VERSION ""

NS_ :

BS_:

BU_: Cockpit PERS Vector__XXX

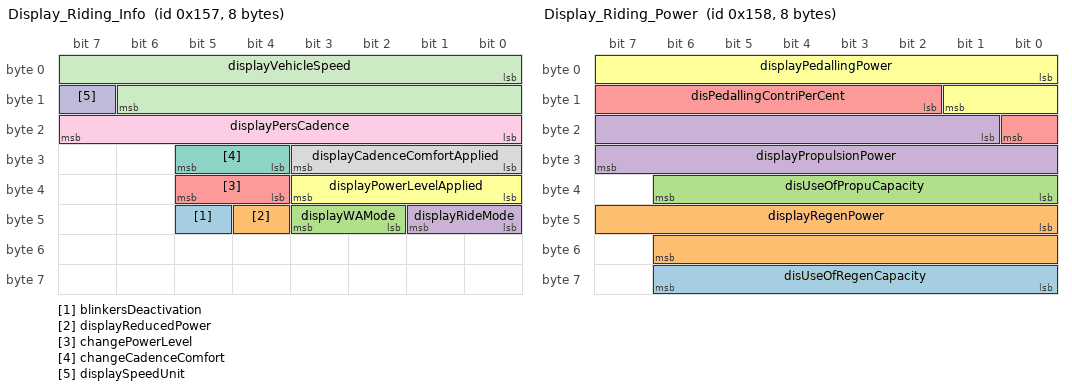
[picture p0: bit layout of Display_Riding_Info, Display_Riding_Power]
BO_ 343 Display_Riding_Info: 8 PERS
 SG_ blinkersDeactivation : 45|1@1+ (1,0) [0|1] "-"  Cockpit
 SG_ displayReducedPower : 44|1@1+ (1,0) [0|1] "-"  Cockpit
 SG_ displayWAMode : 42|2@1+ (1,0) [0|3] "-"  Cockpit
 SG_ displayRideMode : 40|2@1+ (1,0) [0|3] "-"  Cockpit
 SG_ changePowerLevel : 36|2@1+ (1,0) [0|3] "-"  Cockpit
 SG_ displayPowerLevelApplied : 32|4@1+ (1,0) [0|15] "-"  Cockpit
 SG_ changeCadenceComfort : 28|2@1+ (1,0) [0|3] "-"  Cockpit
 SG_ displayCadenceComfortApplied : 24|4@1+ (1,0) [0|15] "-"  Cockpit
 SG_ displayPersCadence : 16|8@1+ (1,0) [0|255] "rpm"  Cockpit
 SG_ displaySpeedUnit : 15|1@1+ (1,0) [0|1] ""  Cockpit
 SG_ displayVehicleSpeed : 0|15@1+ (0.01,-40) [-40|80] "km/h"  Cockpit

BO_ 344 Display_Riding_Power: 8 PERS
 SG_ disUseOfRegenCapacity : 56|7@1+ (1,0) [0|100] "%"  Cockpit
 SG_ displayRegenPower : 40|15@1+ (1,0) [0|32767] "W"  Cockpit
 SG_ disUseOfPropuCapacity : 32|7@1+ (1,0) [0|100] "%"  Cockpit
 SG_ displayPropulsionPower : 17|15@1+ (1,0) [0|32767] "W"  Cockpit
 SG_ disPedallingContriPerCent : 10|7@1+ (1,0) [0|100] "%"  Cockpit
 SG_ displayPedallingPower : 0|10@1+ (1,0) [0|1024] "W"  Cockpit

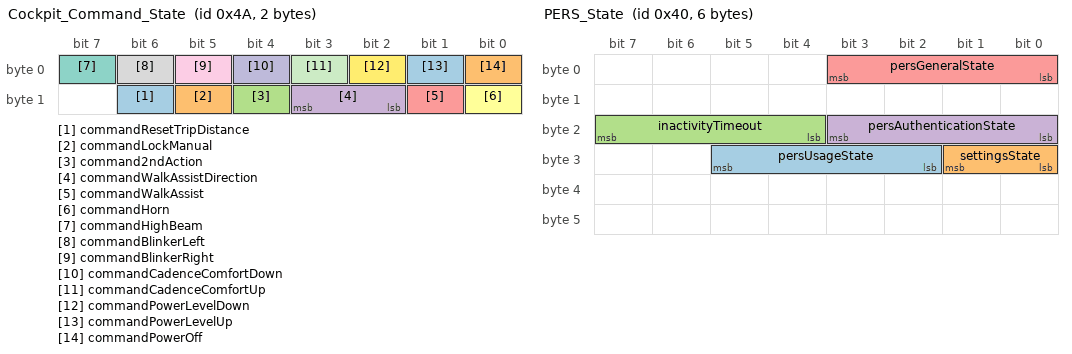
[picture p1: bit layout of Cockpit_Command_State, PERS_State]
BO_ 74 Cockpit_Command_State: 2 Cockpit
 SG_ commandResetTripDistance : 14|1@1+ (1,0) [0|1] ""  PERS
 SG_ commandLockManual : 13|1@1+ (1,0) [0|1] ""  PERS
 SG_ command2ndAction : 12|1@1+ (1,0) [0|1] ""  PERS
 SG_ commandWalkAssistDirection : 10|2@1+ (1,0) [0|3] ""  PERS
 SG_ commandWalkAssist : 9|1@1+ (1,0) [0|1] ""  PERS
 SG_ commandHorn : 8|1@1+ (1,0) [0|1] ""  PERS
 SG_ commandHighBeam : 7|1@1+ (1,0) [0|1] ""  PERS
 SG_ commandBlinkerLeft : 6|1@1+ (1,0) [0|1] ""  PERS
 SG_ commandBlinkerRight : 5|1@1+ (1,0) [0|1] ""  PERS
 SG_ commandCadenceComfortDown : 4|1@1+ (1,0) [0|1] ""  PERS
 SG_ commandCadenceComfortUp : 3|1@1+ (1,0) [0|1] ""  PERS
 SG_ commandPowerLevelDown : 2|1@1+ (1,0) [0|1] ""  PERS
 SG_ commandPowerLevelUp : 1|1@1+ (1,0) [0|1] ""  PERS
 SG_ commandPowerOff : 0|1@1+ (1,0) [0|1] ""  PERS

BO_ 64 PERS_State: 6 PERS
 SG_ persUsageState : 26|4@1+ (1,0) [0|15] "-"  Cockpit
 SG_ settingsState : 24|2@1+ (1,0) [0|3] "-"  Cockpit
 SG_ inactivityTimeout : 20|4@1+ (1,0) [0|15] "sec"  Cockpit
 SG_ persAuthenticationState : 16|4@1+ (1,0) [0|15] ""  Cockpit
 SG_ persGeneralState : 0|4@1+ (1,0) [0|15] ""  Cockpit

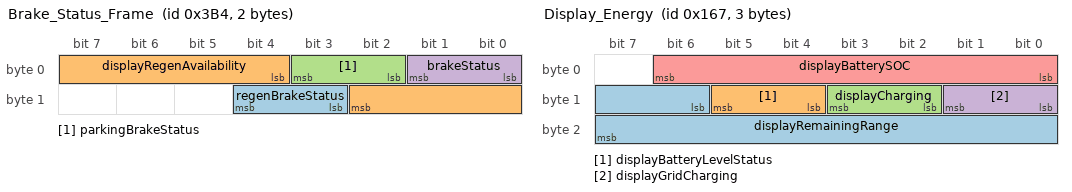
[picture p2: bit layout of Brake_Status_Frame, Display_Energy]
BO_ 948 Brake_Status_Frame: 2 PERS
 SG_ regenBrakeStatus : 11|2@1+ (1,0) [0|3] "-"  Cockpit
 SG_ displayRegenAvailability : 4|7@1+ (1,0) [0|127] "%"  Cockpit
 SG_ parkingBrakeStatus : 2|2@1+ (1,0) [0|3] "-"  Cockpit
 SG_ brakeStatus : 0|2@1+ (1,0) [0|3] "-"  Cockpit

BO_ 952 Odometer: 4 PERS
 SG_ displayOdometer : 0|32@1+ (0.001,0) [0|4294970] "km"  Cockpit

BO_ 953 Trip_info: 4 PERS
 SG_ tripDistance : 0|32@1+ (0.001,0) [0|4294970] "km"  Cockpit

BO_ 359 Display_Energy: 3 PERS
 SG_ displayRemainingRange : 14|10@1+ (1,0) [0|1023] "km"  Cockpit
 SG_ displayBatteryLevelStatus : 12|2@1+ (1,0) [0|3] "-"  Cockpit
 SG_ displayCharging : 10|2@1+ (1,0) [0|3] "-"  Cockpit
 SG_ displayGridCharging : 8|2@1+ (1,0) [0|3] "-"  Cockpit
 SG_ displayBatterySOC : 0|7@1+ (1,0) [0|127] "%"  Cockpit

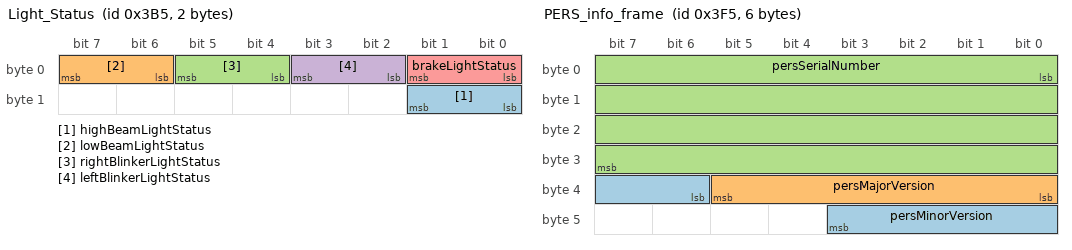
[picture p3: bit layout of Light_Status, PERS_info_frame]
BO_ 949 Light_Status: 2 PERS
 SG_ highBeamLightStatus : 8|2@1+ (1,0) [0|3] ""  Cockpit
 SG_ lowBeamLightStatus : 6|2@1+ (1,0) [0|3] ""  Cockpit
 SG_ rightBlinkerLightStatus : 4|2@1+ (1,0) [0|3] ""  Cockpit
 SG_ leftBlinkerLightStatus : 2|2@1+ (1,0) [0|3] ""  Cockpit
 SG_ brakeLightStatus : 0|2@1+ (1,0) [0|3] ""  Cockpit

BO_ 950 Service_Status_Frame: 1 PERS
 SG_ n4GStatus : 2|2@1+ (1,0) [0|3] "-"  Cockpit
 SG_ bluetoothStatus : 0|2@1+ (1,0) [0|3] "-"  Cockpit

BO_ 1013 PERS_info_frame: 6 PERS
 SG_ persMinorVersion : 38|6@1+ (1,0) [0|63] "-"  Cockpit
 SG_ persMajorVersion : 32|6@1+ (1,0) [0|63] "-"  Cockpit
 SG_ persSerialNumber : 0|32@1+ (1,0) [0|4294967295] "-"  Cockpit

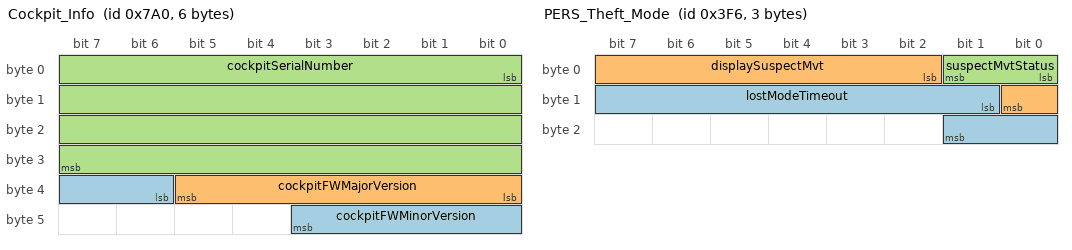
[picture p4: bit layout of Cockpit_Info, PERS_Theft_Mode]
BO_ 1952 Cockpit_Info: 6 Cockpit
 SG_ cockpitFWMinorVersion : 38|6@1+ (1,0) [0|63] "-"  PERS
 SG_ cockpitFWMajorVersion : 32|6@1+ (1,0) [0|63] "-"  PERS
 SG_ cockpitSerialNumber : 0|32@1+ (1,0) [0|4294967295] "-"  PERS

BO_ 1014 PERS_Theft_Mode: 3 PERS
 SG_ lostModeTimeout : 9|9@1+ (1,0) [0|511] "sec"  Cockpit
 SG_ displaySuspectMvt : 2|7@1+ (1,0) [0|100] "%"  Cockpit
 SG_ suspectMvtStatus : 0|2@1+ (1,0) [0|3] ""  Cockpit

BO_ 951 PERS_time_frame: 4 PERS
 SG_ timestamp : 0|32@1+ (1,0) [0|4294967295] "s"  Cockpit

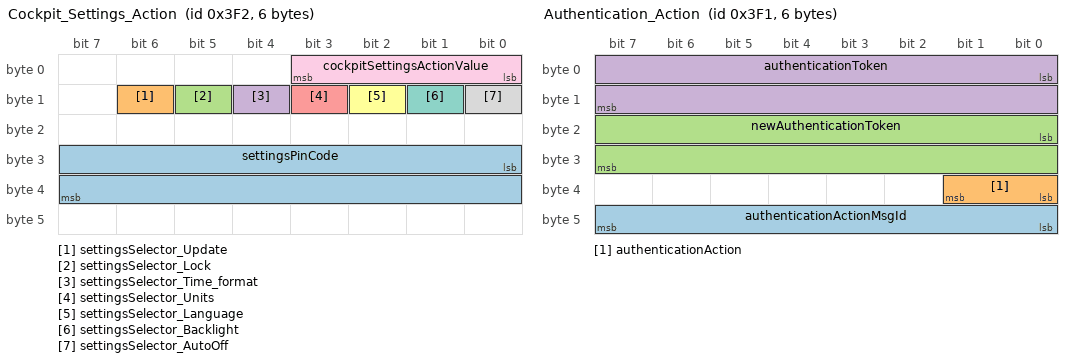
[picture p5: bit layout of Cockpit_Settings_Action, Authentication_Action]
BO_ 1010 Cockpit_Settings_Action: 6 Cockpit
 SG_ settingsPinCode : 24|16@1+ (1,0) [0|65535] "-"  PERS
 SG_ settingsSelector_Update : 14|1@1+ (1,0) [0|1] ""  PERS
 SG_ settingsSelector_Lock : 13|1@1+ (1,0) [0|1] ""  PERS
 SG_ settingsSelector_Time_format : 12|1@1+ (1,0) [0|1] ""  PERS
 SG_ settingsSelector_Units : 11|1@1+ (1,0) [0|1] ""  PERS
 SG_ settingsSelector_Language : 10|1@1+ (1,0) [0|1] ""  PERS
 SG_ settingsSelector_Backlight : 9|1@1+ (1,0) [0|1] ""  PERS
 SG_ settingsSelector_AutoOff : 8|1@1+ (1,0) [0|1] "-"  PERS
 SG_ cockpitSettingsActionValue : 0|4@1+ (1,0) [0|15] "-"  PERS

BO_ 995 Cockpit_Settings_Action_State: 6 PERS
 SG_ displayUpdateConfig m0 : 44|2@1+ (1,0) [0|3] "-"  Cockpit
 SG_ displayLockConfig m0 : 42|2@1+ (1,0) [0|1] "-"  Cockpit
 SG_ displayTimeFormat m0 : 41|1@1+ (1,0) [0|1] "-"  Cockpit
 SG_ displaySpeedUnitConfig m0 : 40|1@1+ (1,0) [0|1] "-"  Cockpit
 SG_ displayLanguage m0 : 36|4@1+ (1,0) [0|15] "-"  Cockpit
 SG_ displayBacklightConfig m0 : 32|4@1+ (1,0) [0|15] "-"  Cockpit
 SG_ displayAutoOffTimeout m0 : 24|8@1+ (1,0) [0|63] "minutes"  Cockpit
 SG_ settingsSelectorRX_Update : 14|1@1+ (1,0) [0|1] ""  Cockpit
 SG_ settingsSelectorRX_Lock : 13|1@1+ (1,0) [0|1] ""  Cockpit
 SG_ settingsSelectorRX_Time_format : 12|1@1+ (1,0) [0|1] ""  Cockpit
 SG_ settingsSelectorRX_Units : 11|1@1+ (1,0) [0|1] ""  Cockpit
 SG_ settingsSelectorRX_Language : 10|1@1+ (1,0) [0|1] ""  Cockpit
 SG_ settingsSelectorRX_Backlight : 9|1@1+ (1,0) [0|1] ""  Cockpit
 SG_ settingsSelectorRX_AutoOff : 8|1@1+ (1,0) [0|1] "-"  Cockpit
 SG_ cockpitSettingPage M : 4|4@1+ (1,0) [0|15] "-"  Cockpit
 SG_ cockpitActionSettingResult : 0|4@1+ (1,0) [0|15] "-"  Cockpit

BO_ 1009 Authentication_Action: 6 Cockpit
 SG_ authenticationActionMsgId : 40|8@1+ (1,0) [0|255] ""  PERS
 SG_ authenticationAction : 32|2@1+ (1,0) [0|3] ""  PERS
 SG_ newAuthenticationToken : 16|16@1+ (1,0) [0|65535] ""  PERS
 SG_ authenticationToken : 0|16@1+ (1,0) [0|65535] ""  PERS

BO_ 993 Authentication_Action_Result: 2 PERS
 SG_ authenticationActionResult : 8|8@1+ (1,0) [0|255] ""  Cockpit
 SG_ authenticationReceivedMsgId : 0|8@1+ (1,0) [0|255] ""  Cockpit

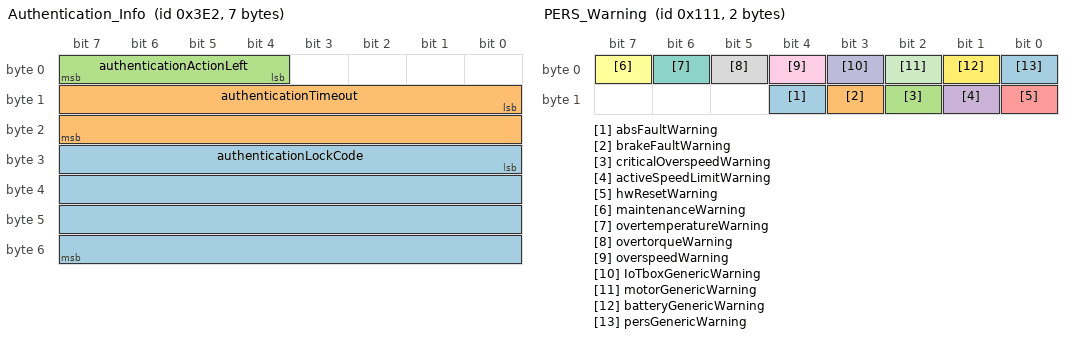
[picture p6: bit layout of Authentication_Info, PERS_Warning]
BO_ 994 Authentication_Info: 7 PERS
 SG_ authenticationLockCode : 24|32@1+ (1,0) [0|4294967295] "-"  Cockpit
 SG_ authenticationTimeout : 8|16@1+ (1,0) [0|65535] "sec"  Cockpit
 SG_ authenticationActionLeft : 4|4@1+ (1,0) [0|16] "-"  Cockpit

BO_ 1011 Recuperation_Action: 8 Cockpit
 SG_ recuperativeToken : 0|64@1+ (1,0) [0|4294967295] ""  PERS

BO_ 1956 Cockpit_Fw_Update_Status: 3 Cockpit
 SG_ fwUpdateLastReceivedBlock : 8|16@1+ (1,0) [0|65535] "-"  PERS
 SG_ fwUpdateStatus : 0|8@1+ (1,0) [0|255] ""  PERS

BO_ 1957 Cockpit_Fw_Update_Command: 5 PERS
 SG_ fwUpdatedBlockCRC16 m6 : 24|16@1+ (1,0) [0|65535] "-"  Cockpit
 SG_ fwUpdateBlockSize m5 : 24|12@1+ (1,1) [1|4096] "-"  Cockpit
 SG_ fwUpdatedBlockId m6 : 8|16@1+ (1,0) [0|65535] "-"  Cockpit
 SG_ fwUpdateBlockId m5 : 8|16@1+ (1,0) [0|65535] "-"  Cockpit
 SG_ fwUpdateCommand M : 0|8@1+ (1,0) [0|32] ""  Cockpit

BO_ 1958 Cockpit_Fw_Update_Binary: 8 PERS
 SG_ fwUpdateBinaryData : 0|64@1+ (1,0) [0|18446744073709551615] "-"  Cockpit

BO_ 1959 Cockpit_Fw_Update_Ack: 2 Cockpit
 SG_ fwUpdateComandResult : 8|4@1+ (1,0) [0|15] "-"  PERS
 SG_ fwUpdateCommandReceived : 0|8@1+ (1,0) [0|255] ""  PERS

BO_ 273 PERS_Warning: 2 PERS
 SG_ absFaultWarning : 12|1@1+ (1,0) [0|1] "-"  Cockpit
 SG_ brakeFaultWarning : 11|1@1+ (1,0) [0|1] "-"  Cockpit
 SG_ criticalOverspeedWarning : 10|1@1+ (1,0) [0|1] "-"  Cockpit
 SG_ activeSpeedLimitWarning : 9|1@1+ (1,0) [0|1] "-"  Cockpit
 SG_ hwResetWarning : 8|1@1+ (1,0) [0|1] "-"  Cockpit
 SG_ maintenanceWarning : 7|1@1+ (1,0) [0|1] "-"  Cockpit
 SG_ overtemperatureWarning : 6|1@1+ (1,0) [0|1] "-"  Cockpit
 SG_ overtorqueWarning : 5|1@1+ (1,0) [0|1] ""  Cockpit
 SG_ overspeedWarning : 4|1@1+ (1,0) [0|1] "-"  Cockpit
 SG_ IoTboxGenericWarning : 3|1@1+ (1,0) [0|1] "-"  Cockpit
 SG_ motorGenericWarning : 2|1@1+ (1,0) [0|1] "-"  Cockpit
 SG_ batteryGenericWarning : 1|1@1+ (1,0) [0|1] "-"  Cockpit
 SG_ persGenericWarning : 0|1@1+ (1,0) [0|1] "-"  Cockpit

BO_ 272 PERS_Error: 1 PERS
 SG_ persGenericError : 0|1@1+ (1,0) [0|1] "-"  Cockpit

BO_ 1955 Cockpit_Heartbeat: 2 Cockpit
 SG_ cockpitHeartbeat : 0|16@1+ (1,0) [0|65535] "-"  PERS

BO_ 1920 PERS_Heartbeat: 2 PERS
 SG_ PERSHeartbeat : 0|16@1+ (1,0) [0|65535] "-"  Vector__XXX

CM_ SG_ 343 blinkersDeactivation "Set to DEACTIVATION when an automatic deactivation of blinkers is required by the PERS.";
CM_ SG_ 343 displayReducedPower "1 - Automatic reduction of propulsion power is applied (active speed limitation, assistance cut-off, propulsion cutoff, battery discharge).";
CM_ SG_ 343 changeCadenceComfort "0 - No†commandCadenceComfortUp or Down have been received 1 - commandCadenceComfortUp or Down have been received but no cadence comfort change applied 2- commandCadenceComfortUp or Down received and cadence comfort change applied";
CM_ SG_ 343 displaySpeedUnit "Speed units, 0-kph 1-mph";
CM_ SG_ 343 displayVehicleSpeed "Speed of the vehicle estimated by the PERS in km/h";
CM_ SG_ 344 disUseOfRegenCapacity "Regen Torque Availability";
CM_ SG_ 344 disUseOfPropuCapacity "Percentage of current vehicule force on its maximum capacity";
CM_ SG_ 344 disPedallingContriPerCent "Percentage of the contribution of the pedalling on vehicule force";
CM_ SG_ 64 persUsageState "ALARM : suspect activity detected by the PERS LOST : Theft confirmed by the user NEUTRALIZED : unusable (e.g. critical error)";
CM_ SG_ 64 settingsState "0 : the user can't enter in the settings menu 3 : the user can enter in the settings menu";
CM_ SG_ 64 inactivityTimeout "Timeout of inactivity.  Necessary for automatic exit of ADM.";
CM_ SG_ 64 persGeneralState "The ON/OFF state of PERS";
CM_ SG_ 948 regenBrakeStatus "Not use : no regen brake Manual available: regen brake requested by the user and available Manual not available : regen brake requested by the user but not available Auto : regen brake activated by the propulsion motor (overspeed)";
CM_ SG_ 948 displayRegenAvailability "Regen brake capability availability in %";
CM_ SG_ 948 parkingBrakeStatus "Brake disable : parking brake not activated Brake enable : parking brake activated";
CM_ SG_ 948 brakeStatus "Brake disable : all brake systems are deactivated Brake enable : a brake system is activated (can be mechanical brake or regen brake)";
CM_ SG_ 953 tripDistance "distance resetable by the user for trip distance feedback";
CM_ SG_ 359 displayRemainingRange "Estimated remaining range";
CM_ SG_ 359 displayGridCharging "Charging on Grid.";
CM_ SG_ 359 displayBatterySOC "in % of SOC";
CM_ SG_ 1013 persMinorVersion "PERS minor version";
CM_ SG_ 1013 persMajorVersion "PERS major version";
CM_ SG_ 1013 persSerialNumber "Serial number of the PERS";
CM_ SG_ 1952 cockpitFWMinorVersion "Cockpit FW minor version";
CM_ SG_ 1952 cockpitFWMajorVersion "Cockpit FW major version";
CM_ SG_ 1952 cockpitSerialNumber "Serial number of the cockpit";
CM_ SG_ 1014 lostModeTimeout "Timer before switching in LOST mode. max : 8min30s";
CM_ SG_ 1014 displaySuspectMvt "Percentage of on going movement comapred to the limit before entering in ALARM mode.† 0% : no ongoing movement 100% : movement max before entering ALARM mode reached.";
CM_ SG_ 1014 suspectMvtStatus "Indicate if the PERS detects a movement which can trigger the ALARM mode";
CM_ SG_ 951 timestamp "Number of seconds elapsed since 01/01/2000 00:00:00. timestamp 2000 epoch";
CM_ SG_ 1010 settingsPinCode "Current authentification pin code. 0 if not required for current action.";
CM_ SG_ 1010 settingsSelector_Update "The request is applied on this setting";
CM_ SG_ 1010 settingsSelector_Lock "The request is applied on this setting";
CM_ SG_ 1010 settingsSelector_Time_format "The request is applied on this setting";
CM_ SG_ 1010 settingsSelector_Units "The request is applied on this setting";
CM_ SG_ 1010 settingsSelector_Language "The request is applied on this setting";
CM_ SG_ 1010 settingsSelector_Backlight "The request is applied on this setting";
CM_ SG_ 1010 settingsSelector_AutoOff "The request is applied on this setting";
CM_ SG_ 995 displayUpdateConfig "Unsupported : manual update configuration is only supported by the APP.";
CM_ SG_ 995 displayLanguage "Fran√ßais English";
CM_ SG_ 995 displayBacklightConfig "Level of brightness";
CM_ SG_ 995 displayAutoOffTimeout "Auto-off timeout value in minutes";
CM_ SG_ 995 settingsSelectorRX_Update "The request was applied on this setting";
CM_ SG_ 995 settingsSelectorRX_Lock "The request was applied on this setting";
CM_ SG_ 995 settingsSelectorRX_Time_format "The request was applied on this setting";
CM_ SG_ 995 settingsSelectorRX_Units "The request was applied on this setting";
CM_ SG_ 995 settingsSelectorRX_Language "The request was applied on this setting";
CM_ SG_ 995 settingsSelectorRX_Backlight "The request was applied on this setting";
CM_ SG_ 995 settingsSelectorRX_AutoOff "The request was applied on this setting";
CM_ SG_ 995 cockpitSettingPage "multiplexer : settings information page to transmit";
CM_ SG_ 995 cockpitActionSettingResult "For settings that required PIN code enter :† PIN_FAULT : error in code PIN and request new PIN enter RESULT_KO : Code PIN error on the last authorizable PIN enter";
CM_ SG_ 1009 authenticationActionMsgId "Message ID of auhentication action message.";
CM_ SG_ 1009 authenticationAction "Action to execute on reception of this message";
CM_ SG_ 1009 newAuthenticationToken "New authentication token";
CM_ SG_ 1009 authenticationToken "Authentication token";
CM_ SG_ 993 authenticationReceivedMsgId "Message ID of auhentication action message.";
CM_ SG_ 994 authenticationTimeout "Timeout before re-authorization of authentication";
CM_ SG_ 994 authenticationActionLeft "Number of authentication attempt left";
CM_ SG_ 1011 recuperativeToken "Recuperative token";
CM_ SG_ 1956 fwUpdateLastReceivedBlock "Last valid received block. This value is valid only during a firmware transfert";
CM_ SG_ 1957 fwUpdatedBlockCRC16 "CRC16 of block transmission";
CM_ SG_ 1957 fwUpdateBlockSize "Size of block transmission";
CM_ SG_ 1957 fwUpdatedBlockId "Block ID to transmit Note : The first block is the header of file";
CM_ SG_ 1957 fwUpdateBlockId "Block ID to transmit Note : The first block is the header of file";
CM_ SG_ 1958 fwUpdateBinaryData "Binary data";
CM_ SG_ 273 criticalOverspeedWarning "vehicle critical overspeed warning";
CM_ SG_ 273 activeSpeedLimitWarning "Active speed limit unavailable";
CM_ SG_ 273 hwResetWarning "PERS HW reset trigger warning";
CM_ SG_ 273 maintenanceWarning "Mid-life maintenance warning";
CM_ SG_ 273 overtemperatureWarning "System is too hot";
CM_ SG_ 273 overspeedWarning "Vehicle overspeed warning";
CM_ SG_ 1955 cockpitHeartbeat "Heartbeat increment.";
CM_ SG_ 1920 PERSHeartbeat "Heartbeat increment.";
BA_DEF_  "BusType" STRING ;
BA_DEF_ BO_  "CANFD_BRS" ENUM  "0","1";
BA_DEF_ BO_  "VFrameFormat" ENUM  "StandardCAN","ExtendedCAN","reserved","reserved","reserved","reserved","reserved","reserved","reserved","reserved","reserved","reserved","reserved","reserved","StandardCAN_FD","ExtendedCAN_FD";
BA_DEF_ BO_  "GenMsgCycleTime" INT 0 65535;
BA_DEF_DEF_  "BusType" "CAN";
BA_DEF_DEF_  "CANFD_BRS" "1";
BA_DEF_DEF_  "GenMsgCycleTime" 0;
BA_ "BusType" "CAN FD";
BA_ "GenMsgCycleTime" BO_ 343 20;
BA_ "VFrameFormat" BO_ 343 0;
BA_ "GenMsgCycleTime" BO_ 344 20;
BA_ "VFrameFormat" BO_ 344 0;
BA_ "VFrameFormat" BO_ 74 0;
BA_ "GenMsgCycleTime" BO_ 64 100;
BA_ "VFrameFormat" BO_ 64 0;
BA_ "GenMsgCycleTime" BO_ 948 20;
BA_ "VFrameFormat" BO_ 948 0;
BA_ "GenMsgCycleTime" BO_ 952 1000;
BA_ "VFrameFormat" BO_ 952 0;
BA_ "GenMsgCycleTime" BO_ 953 1000;
BA_ "VFrameFormat" BO_ 953 0;
BA_ "VFrameFormat" BO_ 359 0;
BA_ "GenMsgCycleTime" BO_ 949 100;
BA_ "VFrameFormat" BO_ 949 0;
BA_ "GenMsgCycleTime" BO_ 950 100;
BA_ "VFrameFormat" BO_ 950 0;
BA_ "VFrameFormat" BO_ 1013 0;
BA_ "VFrameFormat" BO_ 1952 0;
BA_ "GenMsgCycleTime" BO_ 1014 100;
BA_ "VFrameFormat" BO_ 1014 0;
BA_ "GenMsgCycleTime" BO_ 951 1000;
BA_ "VFrameFormat" BO_ 951 0;
BA_ "VFrameFormat" BO_ 1010 0;
BA_ "VFrameFormat" BO_ 995 0;
BA_ "VFrameFormat" BO_ 1009 0;
BA_ "VFrameFormat" BO_ 993 0;
BA_ "GenMsgCycleTime" BO_ 994 100;
BA_ "VFrameFormat" BO_ 994 0;
BA_ "VFrameFormat" BO_ 1011 0;
BA_ "VFrameFormat" BO_ 1956 0;
BA_ "VFrameFormat" BO_ 1957 0;
BA_ "VFrameFormat" BO_ 1958 0;
BA_ "VFrameFormat" BO_ 1959 0;
BA_ "GenMsgCycleTime" BO_ 273 1000;
BA_ "VFrameFormat" BO_ 273 0;
BA_ "GenMsgCycleTime" BO_ 272 1000;
BA_ "VFrameFormat" BO_ 272 0;
BA_ "GenMsgCycleTime" BO_ 1955 100;
BA_ "VFrameFormat" BO_ 1955 0;
BA_ "GenMsgCycleTime" BO_ 1920 50;
BA_ "VFrameFormat" BO_ 1920 0;
VAL_ 343 blinkersDeactivation 0 "NO_REQUEST" 1 "DEACTIVATION" ;
VAL_ 343 displayReducedPower 0 "LIMITATION_OFF" 1 "LIMITATION_ON" ;
VAL_ 343 displayWAMode 0 "WA_NOT_ACTIVE" 1 "WA_NOT_AVAILABLE" 2 "WA_FORWARD_ON" 3 "WA_BACKWARD_ON" ;
VAL_ 343 displayRideMode 0 "RIDE_MODE_NEUTRAL" 1 "RIDE_MODE_BACKWARD" 2 "RIDE_MODE_FORWARD" ;
VAL_ 343 changePowerLevel 0 "NO_REQUEST" 1 "NOT_CHANGE" 2 "CHANGE" ;
VAL_ 343 changeCadenceComfort 0 "NO_REQUEST" 1 "NOT_CHANGE" 2 "CHANGE" ;
VAL_ 343 displaySpeedUnit 0 "DI_SPEED_KPH" 1 "DI_SPEED_MPH" ;
VAL_ 74 commandResetTripDistance 0 "DISABLE" 1 "ENABLE" ;
VAL_ 74 commandLockManual 0 "DISABLE" 1 "ENABLE" ;
VAL_ 74 command2ndAction 0 "DISABLE" 1 "ENABLE" ;
VAL_ 74 commandWalkAssistDirection 0 "DISABLE" 1 "WALK_FORWARD" 2 "WALK_BACKWARD" ;
VAL_ 74 commandWalkAssist 0 "DISABLE" 1 "ENABLE" ;
VAL_ 74 commandHorn 0 "DISABLE" 1 "ENABLE" ;
VAL_ 74 commandHighBeam 0 "DISABLE" 1 "ENABLE" ;
VAL_ 74 commandBlinkerLeft 0 "DISABLE" 1 "ENABLE" ;
VAL_ 74 commandBlinkerRight 0 "DISABLE" 1 "ENABLE" ;
VAL_ 74 commandCadenceComfortDown 0 "DISABLE" 1 "ENABLE" ;
VAL_ 74 commandCadenceComfortUp 0 "DISABLE" 1 "ENABLE" ;
VAL_ 74 commandPowerLevelDown 0 "DISABLE" 1 "ENABLE" ;
VAL_ 74 commandPowerLevelUp 0 "DISABLE" 1 "ENABLE" ;
VAL_ 74 commandPowerOff 0 "DISABLE" 1 "ENABLE" ;
VAL_ 64 persUsageState 0 "PERS_NORMAL" 1 "PERS_ALARM" 2 "PERS_LOST" 3 "PERS_NEUTRALIZED" ;
VAL_ 64 settingsState 0 "NOT_AVAILABLE" 3 "AVAILABLE" ;
VAL_ 64 persAuthenticationState 0 "PERS_UNAUTHENTIFIED" 1 "PERS_AUTHENTIFICATION_FAIL" 2 "PERS_AUTHENTIFIED" 3 "PERS_AUTHENTICATION_LOCKED" ;
VAL_ 64 persGeneralState 0 "PERS_OFF" 1 "PERS_PREP" 2 "PERS_NEUTRAL" 10 "PERS_ACTIVE_DRIVING" ;
VAL_ 948 regenBrakeStatus 0 "NOT_USE" 1 "MANUAL_AVAILABLE" 2 "MANUAL_NOT_AVAILABLE" 3 "AUTO" ;
VAL_ 948 parkingBrakeStatus 0 "BRAKE_DISABLE" 3 "BRAKE_ENABLE" ;
VAL_ 948 brakeStatus 0 "BRAKE_DISABLE" 3 "BRAKE_ENABLE" ;
VAL_ 359 displayBatteryLevelStatus 0 "NORMAL" 1 "LOW_LEVEL" 2 "CRITICAL_LOW_LEVEL" 3 "NO_BATTERY" ;
VAL_ 359 displayCharging 0 "CHARGING_NONE" 1 "CHARGING_IN_PROGRESS" ;
VAL_ 359 displayGridCharging 0 "GRID_CHARGING_NONE" 1 "GRID_CHARGING_IN_PROGRESS" ;
VAL_ 949 highBeamLightStatus 0 "LIGHT_OFF" 1 "LIGHT_ON" 2 "LIGHT_FAULT" ;
VAL_ 949 lowBeamLightStatus 0 "LIGHT_OFF" 1 "LIGHT_ON" 2 "LIGHT_FAULT" ;
VAL_ 949 rightBlinkerLightStatus 0 "LIGHT_OFF" 1 "LIGHT_ON" 2 "LIGHT_FAULT" ;
VAL_ 949 leftBlinkerLightStatus 0 "LIGHT_OFF" 1 "LIGHT_ON" 2 "LIGHT_FAULT" ;
VAL_ 949 brakeLightStatus 0 "LIGHT_OFF" 1 "LIGHT_ON" 2 "LIGHT_FAULT" ;
VAL_ 950 n4GStatus 0 "4G_DISABLE" 1 "4G_ENABLE" 2 "4G_SEARCHING" ;
VAL_ 950 bluetoothStatus 0 "BLE_DISABLE" 1 "BLE_ENABLE" ;
VAL_ 1014 suspectMvtStatus 0 "NO_SUSPECT_MVT" 1 "SUSPECT_MVT_ONGOING" ;
VAL_ 1010 settingsSelector_Update 0 "Not selected" 1 "Selected" ;
VAL_ 1010 settingsSelector_Lock 0 "Not selected" 1 "Selected" ;
VAL_ 1010 settingsSelector_Time_format 0 "Not selected" 1 "Selected" ;
VAL_ 1010 settingsSelector_Units 0 "Not selected" 1 "Selected" ;
VAL_ 1010 settingsSelector_Language 0 "Not selected" 1 "Selected" ;
VAL_ 1010 settingsSelector_Backlight 0 "Not selected" 1 "Selected" ;
VAL_ 1010 settingsSelector_AutoOff 0 "Not selected" 1 "Selected" ;
VAL_ 1010 cockpitSettingsActionValue 0 "NEXT" 1 "PREVIOUS" 2 "GET" 3 "RESET" ;
VAL_ 995 displayUpdateConfig 0 "AUTOMATIC" 1 "SEMI_AUTOMATIC" 2 "UNSUPPORTED" ;
VAL_ 995 displayLockConfig 0 "MANUAL" 1 "AUTOMATIC" ;
VAL_ 995 displayTimeFormat 0 "24H" 1 "12H" ;
VAL_ 995 displaySpeedUnitConfig 0 "DI_SPEED_KPH" 1 "DI_SPEED_MPH" ;
VAL_ 995 displayLanguage 0 "DI_LANG_FR" 1 "DI_LANG_ENG" ;
VAL_ 995 settingsSelectorRX_Update 0 "Not selected" 1 "Selected" ;
VAL_ 995 settingsSelectorRX_Lock 0 "Not selected" 1 "Selected" ;
VAL_ 995 settingsSelectorRX_Time_format 0 "Not selected" 1 "Selected" ;
VAL_ 995 settingsSelectorRX_Units 0 "Not selected" 1 "Selected" ;
VAL_ 995 settingsSelectorRX_Language 0 "Not selected" 1 "Selected" ;
VAL_ 995 settingsSelectorRX_Backlight 0 "Not selected" 1 "Selected" ;
VAL_ 995 settingsSelectorRX_AutoOff 0 "Not selected" 1 "Selected" ;
VAL_ 995 cockpitSettingPage 0 "Page" 1 "Page" 2 "Page" 3 "" ;
VAL_ 995 cockpitActionSettingResult 0 "RESULT_OK" 1 "RESULT_KO" 2 "INVALID_PARAMETER" 3 "PIN_FAULT" ;
VAL_ 1009 authenticationAction 1 "AUTHENTICATE" 2 "CHANGE_TOKEN" ;
VAL_ 993 authenticationActionResult 0 "RESULT_ERROR" 1 "RESULT_AUTHENTICATION_KO" 2 "RESULT_CHANGE_KO" 165 "RESULT_OK" 3 "RESULT_BAD_AUTH_MSG_ID" 4 "RECUPERATIVE_CODE_KO" ;
VAL_ 1956 fwUpdateStatus 1 "FWU_STATUS_READY" 10 "FWU_STATUS_BLOCK_TRANSFERT_IN_PROGRESS" 11 "FWU_STATUS_BLOCK_TRANSFERT_ERROR" 12 "FWU_STATUS_BLOCK_TRANSFERT_SUCCESS" 13 "FWU_STATUS_FILE_TRANSFERT_SUCCESS" 14 "FWU_STATUS_FILE_TRANSFERT_ERROR" 20 "FWU_STATUS_FILE_VERIFY_SUCCESS" 21 "FWU_STATUS_FILE_VERIFY_ERROR" 30 "FWU_STATUS_ACTIVATION_IN_PROGRESS" 31 "FWU_STATUS_ACTIVATION_SUCCESS" 32 "FWU_STATUS_ACTIVATION_ERROR" ;
VAL_ 1957 fwUpdateCommand 1 "CMD_FWU_START_FILE_TRANSFERT" 2 "CMD_FWU_END_FILE_TRANSFERT" 3 "CMD_FWU_ABORT_FILE_TRANSFERT" 5 "CMD_FWU_START_BLOCK_TRANSFERT" 6 "CMD_FWU_END_BLOCK_TRANSFERT" 7 "CMD_FWU_ABORT_BLOCK_TRANSFERT" 10 "CMD_FWU_VERIFY_NEW_FW" 20 "CMD_FWU_ACTIVATE_NEW_FW" 30 "CMD_FWU_GET_STATE" ;
VAL_ 1959 fwUpdateComandResult 0 "CMD_FWU_EXECUTE_ERROR" 1 "CMD_FWU_UNAVAILABLE" 2 "CMD_FWU_UNKNOWN" 15 "CMD_FWU_EXECUTE_SUCCESS" ;
VAL_ 1959 fwUpdateCommandReceived 1 "CMD_FWU_START_FILE_TRANSFERT" 2 "CMD_FWU_END_FILE_TRANSFERT" 3 "CMD_FWU_ABORT_FILE_TRANSFERT" 5 "CMD_FWU_START_BLOCK_TRANSFERT" 6 "CMD_FWU_END_BLOCK_TRANSFERT" 7 "CMD_FWU_ABORT_BLOCK_TRANSFERT" 10 "CMD_FWU_VERIFY_NEW_FW" 20 "CMD_FWU_ACTIVATE_NEW_FW" 255 "CMD_TRANSFERT_DATA" ;
VAL_ 273 absFaultWarning 0 "NOT_ACTIVE" 1 "ACTIVE" ;
VAL_ 273 brakeFaultWarning 0 "NOT_ACTIVE" 1 "ACTIVE" ;
VAL_ 273 criticalOverspeedWarning 0 "NOT_ACTIVE" 1 "ACTIVE" ;
VAL_ 273 activeSpeedLimitWarning 0 "NOT_ACTIVE" 1 "ACTIVE" ;
VAL_ 273 hwResetWarning 0 "NOT_ACTIVE" 1 "ACTIVE" ;
VAL_ 273 maintenanceWarning 0 "NOT_ACTIVE" 1 "ACTIVE" ;
VAL_ 273 overtemperatureWarning 0 "NOT_ACTIVE" 1 "ACTIVE" ;
VAL_ 273 overtorqueWarning 0 "NOT_ACTIVE" 1 "ACTIVE" ;
VAL_ 273 overspeedWarning 0 "NOT_ACTIVE" 1 "ACTIVE" ;
VAL_ 273 IoTboxGenericWarning 0 "NOT_ACTIVE" 1 "ACTIVE" ;
VAL_ 273 motorGenericWarning 0 "NOT_ACTIVE" 1 "ACTIVE" ;
VAL_ 273 batteryGenericWarning 0 "NOT_ACTIVE" 1 "ACTIVE" ;
VAL_ 273 persGenericWarning 0 "NOT_ACTIVE" 1 "ACTIVE" ;
VAL_ 272 persGenericError 0 "NOT_ACTIVE" 1 "ACTIVE" ;
